# ENUMUSAGE register map
Vendor: Test; File version: 1.0
enumeratedValues usage fixture
CPU: CM0
Registers are 32-bit, access not given, no defined reset value unless marked. A register's access mark holds for its fields unless they carry their own. Offsets are from the block's base; lines under a group give offsets from that group; [hi:lo] are bit positions; {n}, {i} and the like mark numbered series; 'fields as' and 'values as' point back to an identical list; <NAME> marks a mode.

## Memory map
0x50000000 P

## P
Base 0x50000000
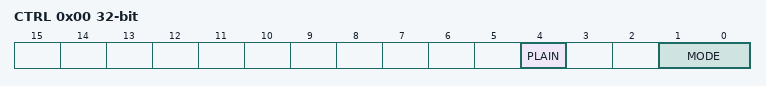
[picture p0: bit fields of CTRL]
0x00 CTRL
  [4] PLAIN — 不带 usage 的普通枚举
    0=OFF; 1=ON
  [1:0] MODE — 读枚举 R0/R1，写枚举 W0/W1
    on read: 0=R0; 1=R1 | on write: 0=W0; 1=W1
